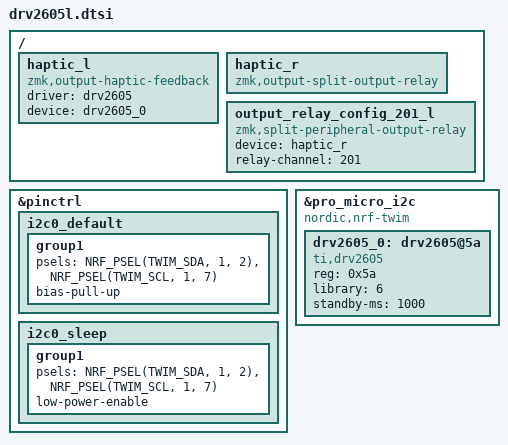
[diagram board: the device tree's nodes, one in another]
/*
 * Copyright (c) 2022 The ZMK Contributors
 *
 * SPDX-License-Identifier: MIT
 */
/ {
    
    haptic_l: haptic_l {
        compatible = "zmk,output-haptic-feedback";
        #binding-cells = <0>;
        driver = "drv2605";
        device = <&drv2605_0>;
    };

    haptic_r: haptic_r {
        compatible = "zmk,output-split-output-relay";
        #binding-cells = <0>;
    };

    output_relay_config_201_l {
        compatible = "zmk,split-peripheral-output-relay";
        device = <&haptic_r>;
        relay-channel = <201>;
    };

};

&pinctrl {
    i2c0_default: i2c0_default {
        group1 {
            psels = <NRF_PSEL(TWIM_SDA, 1, 2)>,
                    <NRF_PSEL(TWIM_SCL, 1, 7)>;
            bias-pull-up;
        };
    };

    i2c0_sleep: i2c0_sleep {
        group1 {
            psels = <NRF_PSEL(TWIM_SDA, 1, 2)>,
                    <NRF_PSEL(TWIM_SCL, 1, 7)>;
            low-power-enable;
        };
    };
};

&pro_micro_i2c {
    status = "okay";
    compatible = "nordic,nrf-twim";

    drv2605_0: drv2605@5a {
        compatible = "ti,drv2605";
        reg = <0x5a>;
        library = <6>;  // LRA
        standby-ms = <1000>;
    };
};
